# TM4C1294NCPDT register map
Vendor: Texas Instruments; File version: 2.2.0.295
CPU: CM4 r0p1, little endian, MPU, FPU, 3 interrupt priority bits
Registers are 32-bit, read-write, no defined reset value unless marked. A register's access mark holds for its fields unless they carry their own. Offsets are from the block's base; [hi:lo] are bit positions; {n}, {i} and the like mark numbered series.

## EMAC0 — EMAC (EMAC0)
Base 0x400EC000
0x00 CFG
0x04 FRAMEFLTR
0x08 HASHTBLH
0x0C HASHTBLL
0x10 MIIADDR
0x14 MIIDATA
0x18 FLOWCTL
0x1C VLANTG
0x24 STATUS
0x28 RWUFF
0x2C PMTCTLSTAT
0x38 RIS
0x3C IM
{0x40+8i} ADDR{i}H (i=0..3)
{0x44+8i} ADDR{i}L (i=0..3)
0xDC WDOGTO
0x100 MMCCTRL
0x104 MMCRXRIS
0x108 MMCTXRIS
0x10C MMCRXIM
0x110 MMCTXIM
0x118 TXCNTGB
0x14C TXCNTSCOL
0x150 TXCNTMCOL
0x164 TXOCTCNTG
0x180 RXCNTGB
0x194 RXCNTCRCERR
0x198 RXCNTALGNERR
0x1C4 RXCNTGUNI
0x584 VLNINCREP
0x588 VLANHASH
0x700 TIMSTCTRL
0x704 SUBSECINC
0x708 TIMSEC
0x70C TIMNANO
0x710 TIMSECU
0x714 TIMNANOU
0x718 TIMADD
0x71C TARGSEC
0x720 TARGNANO
0x724 HWORDSEC
0x728 TIMSTAT
0x72C PPSCTRL
0x760 PPS0INTVL
0x764 PPS0WIDTH
0xC00 DMABUSMOD
0xC04 TXPOLLD
0xC08 RXPOLLD
0xC0C RXDLADDR
0xC10 TXDLADDR
0xC14 DMARIS
0xC18 DMAOPMODE
0xC1C DMAIM
0xC20 MFBOC
0xC24 RXINTWDT
0xC48 HOSTXDESC
0xC4C HOSRXDESC
0xC50 HOSTXBA
0xC54 HOSRXBA
0xFC0 PP
0xFC4 PC
0xFC8 CC
0xFD0 EPHYRIS
0xFD4 EPHYIM
0xFD8 EPHYMISC

## SYSEXC — System Exception Module (SYSEXC)
Base 0x400F9000
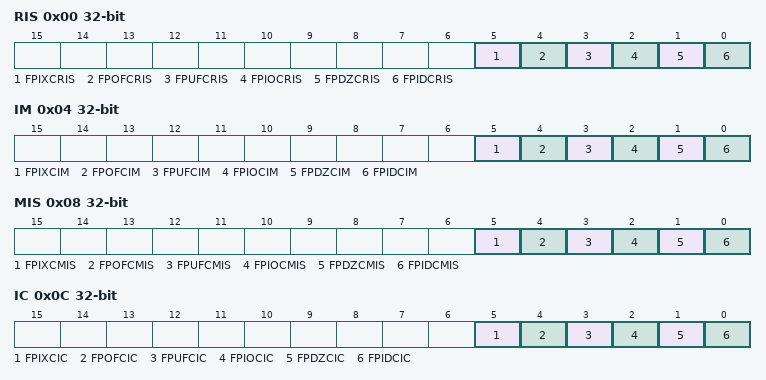
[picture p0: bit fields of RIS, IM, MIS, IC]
0x00 RIS
  [5] FPIXCRIS — Floating-Point Inexact Exception
  [4] FPOFCRIS — Floating-Point Overflow
  [3] FPUFCRIS — Floating-Point Underflow
  [2] FPIOCRIS — Floating-Point Invalid Operation
  [1] FPDZCRIS — Floating-Point Divide By 0
  [0] FPIDCRIS — Floating-Point Input Denormal
0x04 IM
  [5] FPIXCIM — Floating-Point Inexact Exception
  [4] FPOFCIM — Floating-Point Overflow
  [3] FPUFCIM — Floating-Point Underflow
  [2] FPIOCIM — Floating-Point Invalid Operation
  [1] FPDZCIM — Floating-Point Divide By 0
  [0] FPIDCIM — Floating-Point Input Denormal
0x08 MIS
  [5] FPIXCMIS — Floating-Point Inexact Exception
  [4] FPOFCMIS — Floating-Point Overflow
  [3] FPUFCMIS — Floating-Point Underflow
  [2] FPIOCMIS — Floating-Point Invalid Operation
  [1] FPDZCMIS — Floating-Point Divide By 0
  [0] FPIDCMIS — Floating-Point Input Denormal
0x0C IC
  [5] FPIXCIC — Floating-Point Inexact Exception
  [4] FPOFCIC — Floating-Point Overflow
  [3] FPUFCIC — Floating-Point Underflow
  [2] FPIOCIC — Floating-Point Invalid Operation
  [1] FPDZCIC — Floating-Point Divide By 0
  [0] FPIDCIC — Floating-Point Input Denormal

## FLASH — FLASH (FLASH CTRL)
Base 0x400FD000
0x00 FMA
  [19:0] OFFSET — Address Offset
0x04 FMD
  [31:0] DATA — Data Value
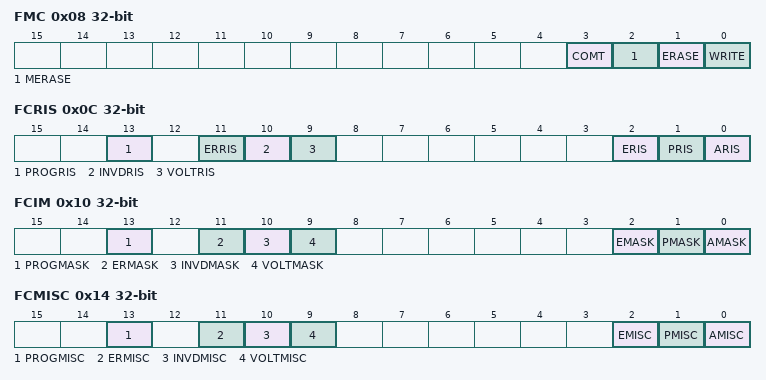
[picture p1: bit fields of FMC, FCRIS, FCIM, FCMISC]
0x08 FMC
  [3] COMT — Commit Register Value
  [2] MERASE — Mass Erase Flash Memory
  [1] ERASE — Erase a Page of Flash Memory
  [0] WRITE — Write a Word into Flash Memory
0x0C FCRIS
  [13] PROGRIS — Program Verify Error Raw
  [11] ERRIS — Erase Verify Error Raw Interrupt
  [10] INVDRIS — Invalid Data Raw Interrupt
  [9] VOLTRIS — Pump Voltage Raw Interrupt
  [2] ERIS — EEPROM Raw Interrupt Status
  [1] PRIS — Programming Raw Interrupt Status
  [0] ARIS — Access Raw Interrupt Status
0x10 FCIM
  [13] PROGMASK — PROGVER Interrupt Mask
  [11] ERMASK — ERVER Interrupt Mask
  [10] INVDMASK — Invalid Data Interrupt Mask
  [9] VOLTMASK — VOLT Interrupt Mask
  [2] EMASK — EEPROM Interrupt Mask
  [1] PMASK — Programming Interrupt Mask
  [0] AMASK — Access Interrupt Mask
0x14 FCMISC
  [13] PROGMISC — PROGVER Masked Interrupt Status
  [11] ERMISC — ERVER Masked Interrupt Status
  [10] INVDMISC — Invalid Data Masked Interrupt
  [9] VOLTMISC — VOLT Masked Interrupt Status and
  [2] EMISC — EEPROM Masked Interrupt Status
  [1] PMISC — Programming Masked Interrupt
  [0] AMISC — Access Masked Interrupt Status
0x20 FMC2
  [0] WRBUF — Buffered Flash Memory Write
0x30 FWBVAL
  [31:0] FWB — Flash Memory Write Buffer
0x3C FLPEKEY
  [15:0] PEKEY — Key Value
0x100 FWBN
  [31:0] DATA
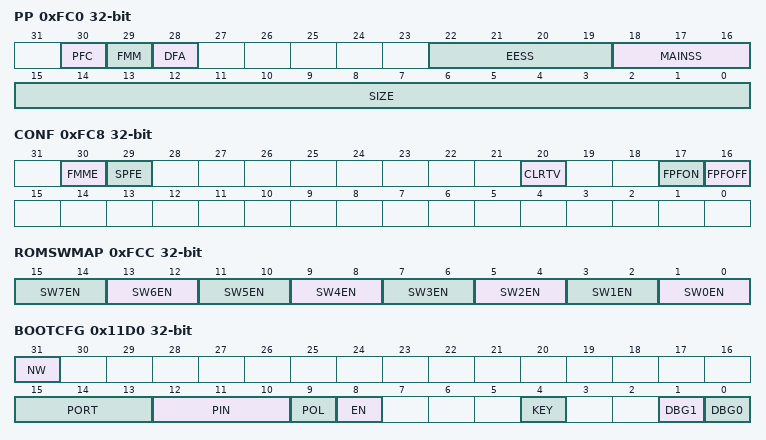
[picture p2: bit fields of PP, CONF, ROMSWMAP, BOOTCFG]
0xFC0 PP
  [30] PFC — Prefetch Buffer Mode
  [29] FMM — Flash Mirror Mode
  [28] DFA — DMA Flash Access
  [22:19] EESS — EEPROM Sector Size of the
    0=1KB; 1=2KB; 2=4KB; 3=8KB
  [18:16] MAINSS — Flash Sector Size of the
    0=1KB; 1=2KB; 2=4KB; 3=8KB; 4=16KB
  [15:0] SIZE — Flash Size
    0x1FF=1MB (1024 KB of Flash)
0xFC4 SSIZE
  [15:0] SIZE — SRAM Size
    0x3FF=256KB (256 KB of SRAM)
0xFC8 CONF
  [30] FMME — Flash Mirror Mode Enable
  [29] SPFE — Single Prefetch Mode Enable
  [20] CLRTV — Clear Valid Tags
  [17] FPFON — Force Prefetch On
  [16] FPFOFF — Force Prefetch Off
0xFCC ROMSWMAP
  [all] fields
    0=NOTVIS (Software region not available to); 1=CORE (Region available to core)
  [2n+1:2n] SW{n}EN (n=0..7) — ROM SW Region {n} Availability
0xFD0 DMASZ
  [17:0] SIZE — uDMA-accessible Memory Size
0xFD4 DMAST
  [28:11] ADDR — Contains the starting address of
0x10D4 RVP
  [31:0] RV — Reset Vector Pointer Address
0x11D0 BOOTCFG
  [31] NW — Not Written
  [15:13] PORT — Boot GPIO Port
    0=A (Port A); 1=B (Port B); 2=C (Port C); 3=D (Port D); 4=E (Port E); 5=F (Port F); 6=G (Port G); 7=H (Port H)
  [12:10] PIN — Boot GPIO Pin
    {v}=Pin {v} (v=0..7)
  [9] POL — Boot GPIO Polarity
  [8] EN — Boot GPIO Enable
  [4] KEY — KEY Select
  [1] DBG1 — Debug Control 1
  [0] DBG0 — Debug Control 0
{0x11E0+4i} USERREG{i} (i=0..3)
  [31:0] DATA — User Data
{0x1200+4i} FMPRE{i} (i=0..7)
{0x1200+4i} FMPRE{i} (i=8..15)
  [31:0] READ_ENABLE — Flash Read Enable
{0x1400+4i} FMPPE{i} (i=0..7)
{0x1400+4i} FMPPE{i} (i=8..15)
  [31:0] PROG_ENABLE — Flash Programming Enable

## UDMA — Micro Direct Memory Access (UDMA)
Base 0x400FF000
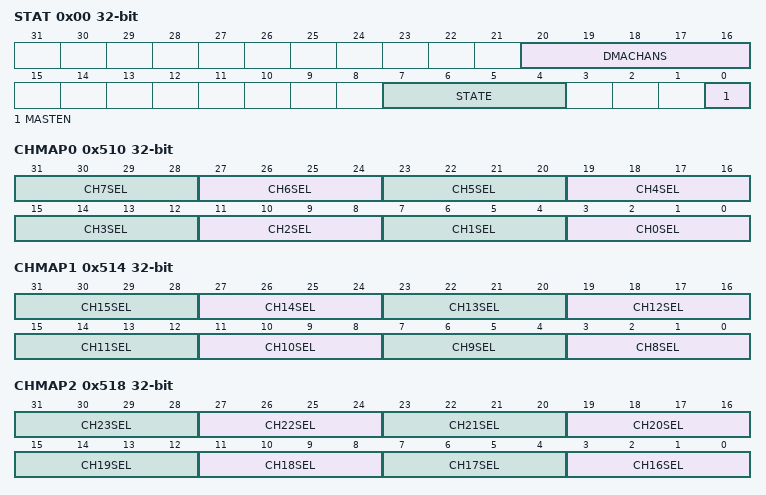
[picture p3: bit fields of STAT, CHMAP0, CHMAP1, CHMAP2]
0x00 STAT
  [20:16] DMACHANS — Available uDMA Channels Minus 1
  [7:4] STATE — Control State Machine Status
    0=IDLE; 1=RD_CTRL (Reading channel controller data); 2=RD_SRCENDP (Reading source end pointer); 3=RD_DSTENDP (Reading destination end pointer); 4=RD_SRCDAT (Reading source data); 5=WR_DSTDAT (Writing destination data); 6=WAIT (Waiting for uDMA request to); 7=WR_CTRL (Writing channel controller data); 8=STALL (Stalled); 9=DONE; 10=UNDEF (Undefined)
  [0] MASTEN — Master Enable Status
0x04 CFG
  [0] MASTEN — Controller Master Enable
0x08 CTLBASE
  [31:10] ADDR — Channel Control Base Address
0x0C ALTBASE
  [31:0] ADDR — Alternate Channel Address
0x10 WAITSTAT
  [31:0] WAITREQ — Channel [n] Wait Status
0x14 SWREQ
  [31:0] VALUE — Channel [n] Software Request
0x18 USEBURSTSET
  [31:0] SET — Channel [n] Useburst Set
0x1C USEBURSTCLR
  [31:0] CLR — Channel [n] Useburst Clear
0x20 REQMASKSET
  [31:0] SET — Channel [n] Request Mask Set
0x24 REQMASKCLR
  [31:0] CLR — Channel [n] Request Mask Clear
0x28 ENASET
  [31:0] SET — Channel [n] Enable Set
0x2C ENACLR
  [31:0] CLR — Clear Channel [n] Enable Clear
0x30 ALTSET
  [31:0] SET — Channel [n] Alternate Set
0x34 ALTCLR
  [31:0] CLR — Channel [n] Alternate Clear
0x38 PRIOSET
  [31:0] SET — Channel [n] Priority Set
0x3C PRIOCLR
  [31:0] CLR — Channel [n] Priority Clear
0x4C ERRCLR
  [0] ERRCLR — uDMA Bus Error Status
0x500 CHASGN
  [31:0] VALUE — Channel [n] Assignment Select
  [0] SECONDARY — Use the secondary channel
0x510 CHMAP0
  [4n+3:4n] CH{n}SEL (n=0..7) — uDMA Channel {n} Source Select
0x514 CHMAP1
  [4n-29:4n-32] CH{n}SEL (n=8..15) — uDMA Channel {n} Source Select
0x518 CHMAP2
  [4n-61:4n-64] CH{n}SEL (n=16..23) — uDMA Channel {n} Source Select
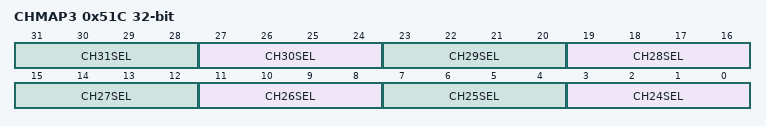
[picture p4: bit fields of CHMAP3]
0x51C CHMAP3
  [4n-93:4n-96] CH{n}SEL (n=24..31) — uDMA Channel {n} Source Select

## CCM0 — EC (CCM0)
Base 0x44030000
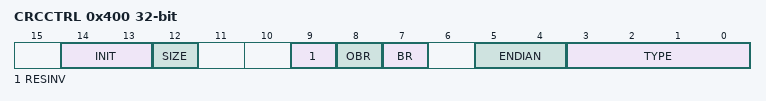
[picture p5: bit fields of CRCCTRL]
0x400 CRCCTRL
  [14:13] INIT — CRC Initialization
    0=SEED (Use the CRCSEED register context); 2=Initialize to all '0s'; 3=Initialize to all '1s'
  [12] SIZE — Input Data Size
  [9] RESINV — Result Inverse Enable
  [8] OBR — Output Reverse Enable
  [7] BR — Bit reverse enable
  [5:4] ENDIAN — Endian Control
    0=SBHW (Configuration unchanged. (B3,); 1=SHW (Bytes are swapped in half-words); 2=SHWNB (Half-words are swapped but bytes); 3=SBSW (Bytes are swapped in half-words)
  [3:0] TYPE — Operation Type
    0=P8055 (Polynomial 0x8005); 1=P1021 (Polynomial 0x1021); 2=P4C11DB7 (Polynomial 0x4C11DB7); 3=P1EDC6F41 (Polynomial 0x1EDC6F41); 8=TCPCHKSUM (TCP checksum)
0x410 CRCSEED
  [31:0] SEED — SEED/Context Value
0x414 CRCDIN
  [31:0] DATAIN — Data Input
0x418 CRCRSLTPP
  [31:0] RSLTPP — Post Processing Result
